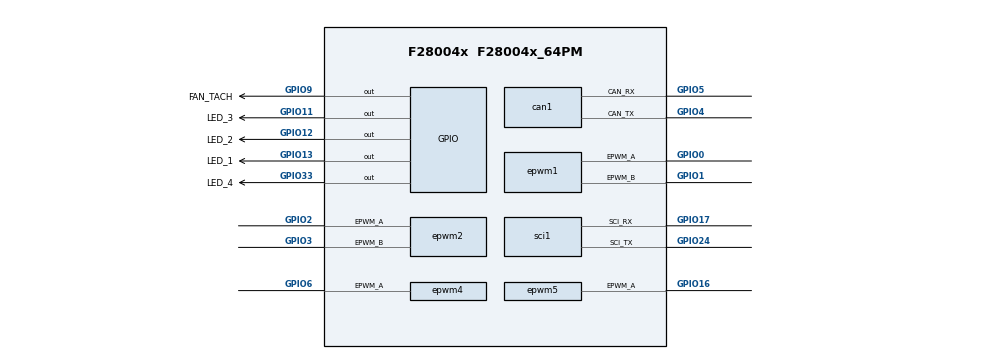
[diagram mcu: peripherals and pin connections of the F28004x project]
/**
 *
 * @cliArgs --device "F28004x" --part "F28004x_64PM" --package "F28004x_64PM" --context "system" --product "C2000WARE@26.01.00.00"
 * @versions {"tool":"1.28.1+4785"}
 */

/**
 * Import the modules used in this configuration.
 */
const adc              = scripting.addModule("/driverlib/adc.js", {}, false);
const adc1             = adc.addInstance();
const adc2             = adc.addInstance();
const adc3             = adc.addInstance();
const asysctl          = scripting.addModule("/driverlib/asysctl.js");
const can              = scripting.addModule("/driverlib/can.js", {}, false);
const can1             = can.addInstance();
const cmpss            = scripting.addModule("/driverlib/cmpss.js", {}, false);
const cmpss1           = cmpss.addInstance();
const cmpss2           = cmpss.addInstance();
const cmpss3           = cmpss.addInstance();
const cmpss4           = cmpss.addInstance();
const cmpss5           = cmpss.addInstance();
const cla              = scripting.addModule("/driverlib/cla.js", {}, false);
const cla1             = cla.addInstance();
const memcfg           = scripting.addModule("/driverlib/memcfg.js");
const cputimer         = scripting.addModule("/driverlib/cputimer.js", {}, false);
const cputimer1        = cputimer.addInstance();
const dma              = scripting.addModule("/driverlib/dma.js", {}, false);
const dma1             = dma.addInstance();
const ecap             = scripting.addModule("/driverlib/ecap.js", {}, false);
const ecap1            = ecap.addInstance();
const epwm             = scripting.addModule("/driverlib/epwm.js", {}, false);
const epwm1            = epwm.addInstance();
const epwm2            = epwm.addInstance();
const epwm3            = epwm.addInstance();
const epwm4            = epwm.addInstance();
const epwm5            = epwm.addInstance();
const epwmxbar         = scripting.addModule("/driverlib/epwmxbar.js", {}, false);
const epwmxbar1        = epwmxbar.addInstance();
const epwmxbar2        = epwmxbar.addInstance();
const gpio             = scripting.addModule("/driverlib/gpio.js", {}, false);
const gpio1            = gpio.addInstance();
const gpio2            = gpio.addInstance();
const gpio3            = gpio.addInstance();
const gpio4            = gpio.addInstance();
const gpio5            = gpio.addInstance();
const inputxbar_input  = scripting.addModule("/driverlib/inputxbar_input.js", {}, false);
const inputxbar_input1 = inputxbar_input.addInstance();
const sci              = scripting.addModule("/driverlib/sci.js", {}, false);
const sci1             = sci.addInstance();

/**
 * Write custom configuration values to the imported modules.
 */
adc1.$name              = "ADC_A";
adc1.adcClockPrescaler  = "ADC_CLK_DIV_2_0";
adc1.interruptPulseMode = "ADC_PULSE_END_OF_CONV";
adc1.enabledSOCs        = ["ADC_SOC_NUMBER0","ADC_SOC_NUMBER1","ADC_SOC_NUMBER2"];
adc1.soc0Name           = "I_BRIDGE_A";
adc1.soc0Channel        = "ADC_CH_ADCIN2";
adc1.soc0Trigger        = "ADC_TRIGGER_EPWM3_SOCA";
adc1.soc0SampleWindow   = 20;
adc1.soc1Name           = "I_IN";
adc1.soc1Channel        = "ADC_CH_ADCIN6";
adc1.soc1Trigger        = "ADC_TRIGGER_EPWM3_SOCB";
adc1.soc1SampleWindow   = 20;
adc1.soc2Name           = "TEMP_FET_A";
adc1.soc2Channel        = "ADC_CH_ADCIN1";
adc1.soc2SampleWindow   = 64;

adc2.$name              = "ADC_B";
adc2.adcBase            = "ADCB_BASE";
adc2.adcClockPrescaler  = "ADC_CLK_DIV_2_0";
adc2.interruptPulseMode = "ADC_PULSE_END_OF_CONV";
adc2.enabledSOCs        = ["ADC_SOC_NUMBER0","ADC_SOC_NUMBER1"];
adc2.soc0Name           = "V_BAT";
adc2.soc0Channel        = "ADC_CH_ADCIN2";
adc2.soc0Trigger        = "ADC_TRIGGER_EPWM3_SOCA";
adc2.soc0SampleWindow   = 20;
adc2.soc1Name           = "V_CAP";
adc2.soc1Channel        = "ADC_CH_ADCIN4";
adc2.soc1Trigger        = "ADC_TRIGGER_EPWM3_SOCB";
adc2.soc1SampleWindow   = 20;

adc3.$name              = "ADC_C";
adc3.interrupt1SOCSource = "ADC_SOC_NUMBER3";
adc3.enableInterrupt1 = true;
adc3.enabledInts = ["ADC_INT_NUMBER1"];
adc3.adcBase            = "ADCC_BASE";
adc3.adcClockPrescaler  = "ADC_CLK_DIV_2_0";
adc3.interruptPulseMode = "ADC_PULSE_END_OF_CONV";
adc3.enabledSOCs        = ["ADC_SOC_NUMBER0","ADC_SOC_NUMBER1","ADC_SOC_NUMBER2","ADC_SOC_NUMBER3","ADC_SOC_NUMBER4"];
adc3.soc0Name           = "I_BRIDGE_B";
adc3.soc0Channel        = "ADC_CH_ADCIN1";
adc3.soc0Trigger        = "ADC_TRIGGER_EPWM3_SOCA";
adc3.soc0SampleWindow   = 20;
adc3.soc1Name           = "I_CAP";
adc3.soc1Channel        = "ADC_CH_ADCIN10";
adc3.soc1Trigger        = "ADC_TRIGGER_EPWM3_SOCB";
adc3.soc1SampleWindow   = 20;
adc3.soc2Name           = "TEMP_L";
adc3.soc2Channel        = "ADC_CH_ADCIN2";
adc3.soc2SampleWindow   = 64;
adc3.soc3Name           = "I_CHASSIS";
adc3.soc3Channel        = "ADC_CH_ADCIN3";
adc3.soc3Trigger        = "ADC_TRIGGER_EPWM3_SOCB";
adc3.soc3SampleWindow   = 20;
adc3.soc4Name           = "TEMP_FET_B";
adc3.soc4Channel        = "ADC_CH_ADCIN4";
adc3.soc4SampleWindow   = 64;

asysctl.analogReference        = "INTERNAL";
asysctl.analogReferenceVoltage = "1P65";

can1.$name                 = "CAN_CHASSIS";
can1.bitRate               = "1000000";
can1.msgObjsUsed           = [1,2,3,4];
can1.can.$assign           = "CANA";
can1.can.can_rxPin.$assign = "GPIO5";
can1.can.can_txPin.$assign = "GPIO4";
can1.msgObj1.$name         = "CAN_RX_COMMAND";
can1.msgObj1.msgID         = 800;
can1.msgObj1.flags         = ["CAN_MSG_OBJ_USE_ID_FILTER"];
can1.msgObj1.msgLen        = 8;
can1.msgObj2.$name         = "CAN_TX_FAST_STATUS";
can1.msgObj2.msgID         = 801;
can1.msgObj2.msgType       = "CAN_MSG_OBJ_TYPE_TX";
can1.msgObj2.msgLen        = 8;
can1.msgObj3.$name         = "CAN_TX_SLOW_STATUS";
can1.msgObj3.msgID         = 802;
can1.msgObj3.msgType       = "CAN_MSG_OBJ_TYPE_TX";
can1.msgObj3.msgLen        = 8;
can1.msgObj4.$name         = "CAN_TX_FAULT";
can1.msgObj4.msgID         = 803;
can1.msgObj4.msgType       = "CAN_MSG_OBJ_TYPE_TX";
can1.msgObj4.msgLen        = 8;

cmpss1.$name               = "CMPSS_I_BRIDGE_A";
cmpss1.enableModule        = true;
cmpss1.asysCMPHPMXSELValue = "1";
cmpss1.asysCMPLPMXSELValue = "1";
cmpss1.dacValHigh          = 2693;
cmpss1.dacValLow           = 1402;
cmpss1.lowCompInvert       = true;
cmpss1.hysteresisVal       = "2";
cmpss1.initFilterHigh      = true;
cmpss1.samplePrescaleHigh  = 3;
cmpss1.sampleWindowHigh    = 5;
cmpss1.thresholdHigh       = 3;
cmpss1.initFilterLow       = true;
cmpss1.samplePrescaleLow   = 3;
cmpss1.sampleWindowLow     = 5;
cmpss1.thresholdLow        = 3;
cmpss1.highCTRIP           = "CMPSS_TRIP_FILTER";
cmpss1.lowCTRIP            = "CMPSS_TRIP_FILTER";

cmpss2.$name              = "CMPSS_I_BRIDGE_B";
cmpss2.cmpssBase          = "CMPSS2_BASE";
cmpss2.enableModule       = true;
cmpss2.dacValHigh         = 2693;
cmpss2.dacValLow          = 1402;
cmpss2.lowCompInvert      = true;
cmpss2.hysteresisVal      = "2";
cmpss2.initFilterHigh     = true;
cmpss2.samplePrescaleHigh = 3;
cmpss2.sampleWindowHigh   = 5;
cmpss2.thresholdHigh      = 3;
cmpss2.initFilterLow      = true;
cmpss2.samplePrescaleLow  = 3;
cmpss2.sampleWindowLow    = 5;
cmpss2.thresholdLow       = 3;
cmpss2.highCTRIP          = "CMPSS_TRIP_FILTER";
cmpss2.lowCTRIP           = "CMPSS_TRIP_FILTER";

cmpss3.$name              = "CMPSS_V_BAT";
cmpss3.cmpssBase          = "CMPSS3_BASE";
cmpss3.enableModule       = true;
cmpss3.dacValHigh         = 3847;
cmpss3.dacValLow          = 2606;
cmpss3.lowCompInvert      = true;
cmpss3.hysteresisVal      = "2";
cmpss3.initFilterHigh     = true;
cmpss3.samplePrescaleHigh = 3;
cmpss3.sampleWindowHigh   = 5;
cmpss3.thresholdHigh      = 3;
cmpss3.initFilterLow      = true;
cmpss3.samplePrescaleLow  = 3;
cmpss3.sampleWindowLow    = 5;
cmpss3.thresholdLow       = 3;
cmpss3.highCTRIP          = "CMPSS_TRIP_FILTER";
cmpss3.lowCTRIP           = "CMPSS_TRIP_FILTER";

cmpss4.$name         = "CMPSS_V_CAP";
cmpss4.cmpssBase     = "CMPSS4_BASE";
cmpss4.enableModule  = true;
cmpss4.hysteresisVal = "2";

cmpss5.$name         = "CMPSS_I_CAP";
cmpss5.cmpssBase     = "CMPSS7_BASE";
cmpss5.enableModule  = true;
cmpss5.dacValLow     = 4095;
cmpss5.lowCompInvert = true;
cmpss5.hysteresisVal = "2";

cputimer1.$name        = "TIMER_BACKGROUND_1KHZ";
cputimer1.cputimerBase = "CPUTIMER1_BASE";
cputimer1.timerPeriod  = 99999;
cputimer1.enableInterrupt = false;
cputimer1.registerInterrupts = false;
cputimer1.startTimer   = true;

ecap1.$name               = "FAN_TACH_CAPTURE";
ecap1.ecapInput           = "ECAP_INPUT_INPUTXBAR7";
ecap1.eventStop           = "ECAP_EVENT_4";
ecap1.counterResetOnEvent = ["ECAP_EVENT_1","ECAP_EVENT_2","ECAP_EVENT_3","ECAP_EVENT_4"];
ecap1.syncOutMode         = "ECAP_SYNC_OUT_DISABLED";
ecap1.resetCounters       = true;
ecap1.useInterrupts       = false;

epwm.generateInitFunctions = true;

// 功率桥：100 MHz / (285 + 1) = 349.650 kHz，50 ns 互补死区。
// HRPWM 在死区输出后调整高侧上升沿/低侧下降沿；两路比较值由应用同步更新。
epwm1.$name                                                         = "PWM_BRIDGE_A";
epwm1.hrpwm_cmpbHR = 1;
epwm1.hrpwm_cmpaHR = 1;
epwm1.hrpwm_edgeModeB = "HRPWM_MEP_CTRL_FALLING_EDGE";
epwm1.hrpwm_edgeModeA = "HRPWM_MEP_CTRL_RISING_EDGE";
epwm1.hrpwm_autoConv = true;
epwm1.hrpwm_enable = true;
epwm1.epwmCounterCompare_cmpB = 143;
epwm1.epwmTimebase_counterMode = "EPWM_COUNTER_MODE_UP";
epwm1.epwmTimebase_periodLoadMode = "EPWM_PERIOD_DIRECT_LOAD";
epwm1.useInterfacePins                                              = ["EPWM#_A","EPWM#_B"];
epwm1.epwmTimebase_hsClockDiv                                       = "EPWM_HSCLOCK_DIVIDER_1";
epwm1.epwmTimebase_period = 285;
epwm1.epwmTimebase_syncOutPulseMode                                 = "EPWM_SYNC_OUT_PULSE_ON_COUNTER_ZERO";
epwm1.epwmCounterCompare_cmpA = 143;
epwm1.epwmActionQualifier_EPWM_AQ_OUTPUT_A_ON_TIMEBASE_ZERO = "EPWM_AQ_OUTPUT_LOW";
epwm1.epwmActionQualifier_EPWM_AQ_OUTPUT_A_ON_TIMEBASE_UP_CMPA = "EPWM_AQ_OUTPUT_HIGH";
epwm1.epwmDeadband_polarityFED                                      = "EPWM_DB_POLARITY_ACTIVE_LOW";
epwm1.epwmDeadband_enableRED                                        = true;
epwm1.epwmDeadband_enableFED                                        = true;
epwm1.epwmDeadband_delayRED                                         = 5;
epwm1.epwmDeadband_delayFED                                         = 5;
epwm1.epwmTripZone_EPWM_TZ_ACTION_EVENT_TZA                         = "EPWM_TZ_ACTION_LOW";
epwm1.epwmTripZone_EPWM_TZ_ACTION_EVENT_TZB                         = "EPWM_TZ_ACTION_LOW";
epwm1.epwmTripZone_EPWM_TZ_ACTION_EVENT_DCAEVT1 = "EPWM_TZ_ACTION_DISABLE";
epwm1.epwmTripZone_EPWM_TZ_ACTION_EVENT_DCAEVT2 = "EPWM_TZ_ACTION_DISABLE";
epwm1.epwmTripZone_EPWM_TZ_ACTION_EVENT_DCBEVT1 = "EPWM_TZ_ACTION_DISABLE";
epwm1.epwmTripZone_EPWM_TZ_ACTION_EVENT_DCBEVT2 = "EPWM_TZ_ACTION_DISABLE";
epwm1.epwmTripZone_cbcSource = [];
epwm1.epwmTripZone_oneShotSource = [];
epwm1.epwm.$assign                                                  = "EPWM1";
epwm1.epwm.epwm_aPin.$assign                                        = "GPIO0";
epwm1.epwm.epwm_bPin.$assign                                        = "GPIO1";

epwm2.$name                                                         = "PWM_BRIDGE_B";
epwm2.epwmTimebase_counterValue = 143;
epwm2.hrpwm_cmpbHR = 1;
epwm2.hrpwm_cmpaHR = 1;
epwm2.hrpwm_edgeModeB = "HRPWM_MEP_CTRL_FALLING_EDGE";
epwm2.hrpwm_edgeModeA = "HRPWM_MEP_CTRL_RISING_EDGE";
epwm2.hrpwm_autoConv = true;
epwm2.hrpwm_enable = true;
epwm2.epwmCounterCompare_cmpB = 143;
epwm2.epwmTimebase_counterMode = "EPWM_COUNTER_MODE_UP";
epwm2.epwmTimebase_periodLoadMode = "EPWM_PERIOD_DIRECT_LOAD";
epwm2.useInterfacePins                                              = ["EPWM#_A","EPWM#_B"];
epwm2.epwmTimebase_hsClockDiv                                       = "EPWM_HSCLOCK_DIVIDER_1";
epwm2.epwmTimebase_period = 285;
epwm2.epwmTimebase_phaseEnable                                      = true;
epwm2.epwmTimebase_syncOutPulseMode                                 = "EPWM_SYNC_OUT_PULSE_ON_EPWMxSYNCIN";
epwm2.epwmCounterCompare_cmpA = 143;
epwm2.epwmActionQualifier_EPWM_AQ_OUTPUT_A_ON_TIMEBASE_ZERO = "EPWM_AQ_OUTPUT_LOW";
epwm2.epwmActionQualifier_EPWM_AQ_OUTPUT_A_ON_TIMEBASE_UP_CMPA = "EPWM_AQ_OUTPUT_HIGH";
epwm2.epwmDeadband_polarityFED                                      = "EPWM_DB_POLARITY_ACTIVE_LOW";
epwm2.epwmDeadband_enableRED                                        = true;
epwm2.epwmDeadband_enableFED                                        = true;
epwm2.epwmDeadband_delayRED                                         = 5;
epwm2.epwmDeadband_delayFED                                         = 5;
epwm2.epwmTripZone_EPWM_TZ_ACTION_EVENT_TZA                         = "EPWM_TZ_ACTION_LOW";
epwm2.epwmTripZone_EPWM_TZ_ACTION_EVENT_TZB                         = "EPWM_TZ_ACTION_LOW";
epwm2.epwmTripZone_EPWM_TZ_ACTION_EVENT_DCAEVT1 = "EPWM_TZ_ACTION_DISABLE";
epwm2.epwmTripZone_EPWM_TZ_ACTION_EVENT_DCAEVT2 = "EPWM_TZ_ACTION_DISABLE";
epwm2.epwmTripZone_EPWM_TZ_ACTION_EVENT_DCBEVT1 = "EPWM_TZ_ACTION_DISABLE";
epwm2.epwmTripZone_EPWM_TZ_ACTION_EVENT_DCBEVT2 = "EPWM_TZ_ACTION_DISABLE";
epwm2.epwmTripZone_cbcSource = [];
epwm2.epwmTripZone_oneShotSource = [];
// 180° = 143 TBCLK；加 2 拍补偿 F28004x 内部同步延迟。
epwm2.epwmTimebase_phaseShift = 145;
epwm2.epwm.$assign                                                  = "EPWM2";
epwm2.epwm.epwm_aPin.$assign                                        = "GPIO2";
epwm2.epwm.epwm_bPin.$assign                                        = "GPIO3";

epwm3.$name                                             = "PWM_ADC_TRIGGER";
epwm3.epwmTimebase_counterMode = "EPWM_COUNTER_MODE_UP";
epwm3.epwmTimebase_periodLoadMode = "EPWM_PERIOD_DIRECT_LOAD";
epwm3.useCase                                           = "CUSTOM";
epwm3.epwmTimebase_hsClockDiv                           = "EPWM_HSCLOCK_DIVIDER_1";
epwm3.epwmTimebase_period = 285;
epwm3.epwmTimebase_phaseEnable                          = true;
epwm3.epwmCounterCompare_cmpA = 71;
epwm3.epwmCounterCompare_cmpB = 214;
epwm3.epwmEventTrigger_EPWM_SOC_A_triggerEnable         = true;
epwm3.epwmEventTrigger_EPWM_SOC_A_triggerSource         = "EPWM_SOC_TBCTR_U_CMPA";
epwm3.epwmEventTrigger_EPWM_SOC_A_triggerEventPrescalar = "7";
epwm3.epwmEventTrigger_EPWM_SOC_B_triggerEnable         = true;
epwm3.epwmEventTrigger_EPWM_SOC_B_triggerSource         = "EPWM_SOC_TBCTR_U_CMPB";
epwm3.epwmEventTrigger_EPWM_SOC_B_triggerEventPrescalar = "7";
// ePWM1 -> ePWM2 -> ePWM3 级联同步；七分频采样为 49.950 kHz。
epwm3.epwmTimebase_phaseShift = 4;
epwm3.epwm.$assign                                      = "EPWM3";

epwm4.$name                                                        = "PWM_BUZZER";
epwm4.useCase                                                      = "CUSTOM";
epwm4.useInterfacePins                                             = ["EPWM#_A"];
epwm4.epwmTimebase_hsClockDiv                                      = "EPWM_HSCLOCK_DIVIDER_1";
epwm4.epwmTimebase_period                                          = 1561;
epwm4.epwmTimebase_counterMode                                     = "EPWM_COUNTER_MODE_UP";
epwm4.epwmCounterCompare_cmpA                                      = 781;
epwm4.epwmActionQualifier_EPWM_AQ_OUTPUT_A_ON_TIMEBASE_ZERO        = "EPWM_AQ_OUTPUT_HIGH";
epwm4.epwmActionQualifier_EPWM_AQ_OUTPUT_A_ON_TIMEBASE_UP_CMPA     = "EPWM_AQ_OUTPUT_LOW";
epwm4.epwmActionQualifier_EPWM_AQ_OUTPUT_A_continuousSwForceAction = "EPWM_AQ_SW_OUTPUT_LOW";
// 100 MHz / 1562 = 64.020 kHz PWM，八分频中断按 8.003 kHz 播放语音。
epwm4.epwmTimebase_periodLoadMode = "EPWM_PERIOD_DIRECT_LOAD";
epwm4.epwmActionQualifier_continousSwForceReloadMode = "EPWM_AQ_SW_IMMEDIATE_LOAD";
epwm4.epwmEventTrigger_enableInterrupt = true;
epwm4.epwmEventTrigger_interruptSource = "EPWM_INT_TBCTR_ZERO";
epwm4.epwmEventTrigger_interruptEventCount = "8";
epwm4.epwm.$assign                                                 = "EPWM4";
epwm4.epwm.epwm_aPin.$assign                                       = "GPIO6";

epwm5.$name                                                        = "PWM_FAN";
epwm5.useCase                                                      = "CUSTOM";
epwm5.useInterfacePins                                             = ["EPWM#_A"];
epwm5.epwmTimebase_hsClockDiv                                      = "EPWM_HSCLOCK_DIVIDER_1";
epwm5.epwmTimebase_period                                          = 3999;
epwm5.epwmTimebase_counterMode                                     = "EPWM_COUNTER_MODE_UP";
epwm5.epwmActionQualifier_EPWM_AQ_OUTPUT_A_ON_TIMEBASE_ZERO        = "EPWM_AQ_OUTPUT_HIGH";
epwm5.epwmActionQualifier_EPWM_AQ_OUTPUT_A_ON_TIMEBASE_UP_CMPA     = "EPWM_AQ_OUTPUT_LOW";
epwm5.epwmActionQualifier_EPWM_AQ_OUTPUT_A_continuousSwForceAction = "EPWM_AQ_SW_OUTPUT_LOW";
epwm5.epwm.$assign                                                 = "EPWM5";
epwm5.epwm.epwm_aPin.$assign                                       = "GPIO16";

epwmxbar1.$name           = "EPWM_XBAR_PEAK_CURRENT";
epwmxbar1.tripInput       = "XBAR_TRIP7";
epwmxbar1.useSourceSelect = true;
epwmxbar1.sourceSignals   = ["CMPSS1_CTRIPH_OR_L","CMPSS2_CTRIPH_OR_L"];

epwmxbar2.$name           = "EPWM_XBAR_HARD_FAULT";
epwmxbar2.useSourceSelect = true;
epwmxbar2.sourceSignals   = ["CMPSS3_CTRIPH","CMPSS4_CTRIPH","CMPSS7_CTRIPH_OR_L"];

gpio1.$name             = "LED_1";
gpio1.direction         = "GPIO_DIR_MODE_OUT";
gpio1.writeInitialValue = true;
gpio1.initialValue      = 1;
gpio1.gpioPin.$assign   = "GPIO13";

gpio2.$name             = "LED_2";
gpio2.direction         = "GPIO_DIR_MODE_OUT";
gpio2.writeInitialValue = true;
gpio2.initialValue      = 1;
gpio2.gpioPin.$assign   = "GPIO12";

gpio3.$name             = "LED_3";
gpio3.direction         = "GPIO_DIR_MODE_OUT";
gpio3.writeInitialValue = true;
gpio3.initialValue      = 1;
gpio3.gpioPin.$assign   = "GPIO11";

gpio4.$name             = "LED_4";
gpio4.direction         = "GPIO_DIR_MODE_OUT";
gpio4.writeInitialValue = true;
gpio4.initialValue      = 1;
gpio4.gpioPin.$assign   = "GPIO33";

gpio5.$name           = "FAN_TACH";
gpio5.gpioPin.$assign = "GPIO9";

inputxbar_input1.$name          = "FAN_TACH_INPUT";
inputxbar_input1.inputxbarInput = "XBAR_INPUT7";
inputxbar_input1.inputxbarGpio  = "GPIO9";

sci1.$name                 = "SCI_DEBUG";
sci1.useInterrupts         = false;
sci1.baudRates             = 1562500;
sci1.sci.$assign           = "SCIA";
sci1.sci.sci_rxPin.$assign = "GPIO17";
sci1.sci.sci_txPin.$assign = "GPIO24";
sci1.rxQual.$name          = "myGPIOQUAL0";
sci1.txQual.$name          = "myGPIOQUAL1";

// ADCC1 -> DMA CH1：三个 ADC 各取 RESULT0..3，完成后由 CPU 提交七路码并触发 CLA。
dma1.$name = "DMA_ADC_CAPTURE";
dma1.dmaBase = "DMA_CH1_BASE";
dma1.srcAddressInputMode = "MANUAL";
dma1.srcAddressManual = 0xB00;
dma1.destAddressInputMode = "VARIABLE";
dma1.destAddressVariable = "AdcDma_Destination";
dma1.burstSize = 4;
dma1.srcBurstStep = 1;
dma1.destBurstStep = 1;
dma1.transferSize = 3;
dma1.srcTransferStep = 29;
dma1.destTransferStep = 1;
dma1.triggerSource = "DMA_TRIGGER_ADCC1";
dma1.oneShotConfig = "DMA_CFG_ONESHOT_ENABLE";
dma1.continuousModeConfig = "DMA_CFG_CONTINUOUS_DISABLE";
dma1.databusWidthConfig = "DMA_CFG_SIZE_16BIT";
dma1.useInterrupts = true;
dma1.enableInterrupts = true;
dma1.registerInterrupts = false;
dma1.interruptMode = "DMA_INT_AT_END";
dma1.enableOverrunInterrupt = true;
dma1.enableTriggers = true;
dma1.startChannel = false;
dma1.emulationMode = "DMA_EMULATION_STOP";

// CLA Task 1：仅在 DMA 整帧提交完成后软件触发；Task 8：一次性初始化。
cla1.$name = "CLA_ADC";
cla1.trigger_CLA_TASK_1 = "CLA_TRIGGER_SOFTWARE";
cla1.enable_CLA_TASK_1 = true;
cla1.cpuint_CLA_TASK_1 = false;
cla1.enable_CLA_TASK_2 = false;
cla1.cpuint_CLA_TASK_2 = false;
cla1.enable_CLA_TASK_3 = false;
cla1.cpuint_CLA_TASK_3 = false;
cla1.enable_CLA_TASK_4 = false;
cla1.cpuint_CLA_TASK_4 = false;
cla1.enable_CLA_TASK_5 = false;
cla1.cpuint_CLA_TASK_5 = false;
cla1.enable_CLA_TASK_6 = false;
cla1.cpuint_CLA_TASK_6 = false;
cla1.enable_CLA_TASK_7 = false;
cla1.cpuint_CLA_TASK_7 = false;
cla1.enable_CLA_TASK_8 = true;
cla1.cpuint_CLA_TASK_8 = false;
memcfg.config_MEMCFG_SECT_LS0 = "CLA_prog";
memcfg.config_MEMCFG_SECT_LS1 = "CLA_prog";
memcfg.config_MEMCFG_SECT_LS2 = "CLA_data";
memcfg.init_MEMCFG_SECT_MSGCPUTOCLA1 = true;
memcfg.init_MEMCFG_SECT_MSGCLA1TOCPU = true;
